# PRU_ICSSG0_PR1_CFG_SLV_local register map
Vendor: Texas Instruments
Peripheral module from a debugger description file (folder J7ES).
Registers are 32-bit, read-write, reset 0x0 unless marked. A register's access mark holds for its fields unless they carry their own. Offsets are as the file gives them; lines under a group give offsets from that group; [hi:lo] are bit positions; {n}, {i} and the like mark numbered series; 'fields as' and 'values as' point back to an identical list; <NAME> marks a mode.

## PRU_ICSSG0_PR1_CFG_SLV
0x00 ICSSG_PID_REG ro reset 0x6B00C900 — PID Register
  [31:0] ICSS_IDVER — Module ID field
0x04 ICSSG_HWDIS_REG ro reset not defined — HW DIS Register
  [7:0] HWDIS — HW Disable Observation
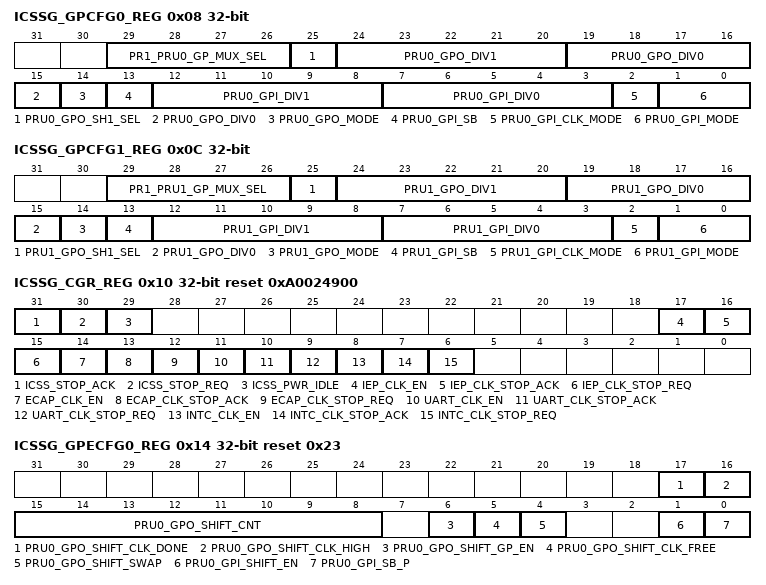
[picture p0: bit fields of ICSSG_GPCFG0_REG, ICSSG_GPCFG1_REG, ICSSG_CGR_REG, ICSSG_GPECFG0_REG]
0x08 ICSSG_GPCFG0_REG access not given — gpcfg0 Register
  [29:26] PR1_PRU0_GP_MUX_SEL rw
  [25] PRU0_GPO_SH1_SEL ro
  [24:20] PRU0_GPO_DIV1 rw
  [19:15] PRU0_GPO_DIV0 rw
  [14] PRU0_GPO_MODE rw
  [13] PRU0_GPI_SB — (access RW1C)
  [12:8] PRU0_GPI_DIV1 rw
  [7:3] PRU0_GPI_DIV0 rw
  [2] PRU0_GPI_CLK_MODE rw
  [1:0] PRU0_GPI_MODE rw
0x0C ICSSG_GPCFG1_REG access not given — gpcfg1 Register
  [29:26] PR1_PRU1_GP_MUX_SEL rw
  [25] PRU1_GPO_SH1_SEL ro
  [24:20] PRU1_GPO_DIV1 rw
  [19:15] PRU1_GPO_DIV0 rw
  [14] PRU1_GPO_MODE rw
  [13] PRU1_GPI_SB — (access RW1C)
  [12:8] PRU1_GPI_DIV1 rw
  [7:3] PRU1_GPI_DIV0 rw
  [2] PRU1_GPI_CLK_MODE rw
  [1:0] PRU1_GPI_MODE rw
0x10 ICSSG_CGR_REG access per field reset 0xA0024900 — cgr Register
  [31] ICSS_STOP_ACK rw, [30] ICSS_STOP_REQ ro, [29] ICSS_PWR_IDLE rw, [17] IEP_CLK_EN rw, [16] IEP_CLK_STOP_ACK ro, [15] IEP_CLK_STOP_REQ rw, [14] ECAP_CLK_EN rw, [13] ECAP_CLK_STOP_ACK ro, [12] ECAP_CLK_STOP_REQ rw, [11] UART_CLK_EN rw, [10] UART_CLK_STOP_ACK ro, [9] UART_CLK_STOP_REQ rw, [8] INTC_CLK_EN rw, [7] INTC_CLK_STOP_ACK ro, [6] INTC_CLK_STOP_REQ rw
0x14 ICSSG_GPECFG0_REG reset 0x23 — gpecfg0 Register
  [17] PRU0_GPO_SHIFT_CLK_DONE, [16] PRU0_GPO_SHIFT_CLK_HIGH, [15:8] PRU0_GPO_SHIFT_CNT, [6] PRU0_GPO_SHIFT_GP_EN, [5] PRU0_GPO_SHIFT_CLK_FREE, [4] PRU0_GPO_SHIFT_SWAP, [1] PRU0_GPI_SHIFT_EN, [0] PRU0_GPI_SB_P
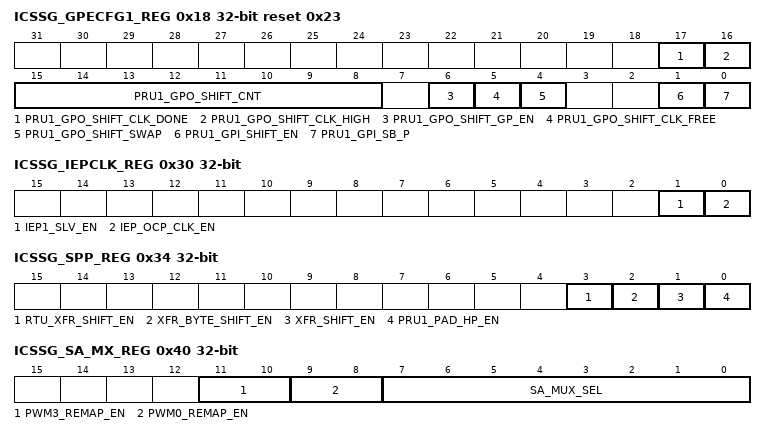
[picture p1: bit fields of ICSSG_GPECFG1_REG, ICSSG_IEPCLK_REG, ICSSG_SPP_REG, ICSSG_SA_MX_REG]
0x18 ICSSG_GPECFG1_REG reset 0x23 — gpecfg1 Register
  [17] PRU1_GPO_SHIFT_CLK_DONE, [16] PRU1_GPO_SHIFT_CLK_HIGH, [15:8] PRU1_GPO_SHIFT_CNT, [6] PRU1_GPO_SHIFT_GP_EN, [5] PRU1_GPO_SHIFT_CLK_FREE, [4] PRU1_GPO_SHIFT_SWAP, [1] PRU1_GPI_SHIFT_EN, [0] PRU1_GPI_SB_P
0x2C ICSSG_MII_RT_REG reset 0x1 — mii_rt Register
  [0] MII_RT_EVENT_EN
0x30 ICSSG_IEPCLK_REG — iepclk Register
  [1] IEP1_SLV_EN, [0] IEP_OCP_CLK_EN
0x34 ICSSG_SPP_REG — spp Register
  [3] RTU_XFR_SHIFT_EN, [2] XFR_BYTE_SHIFT_EN, [1] XFR_SHIFT_EN, [0] PRU1_PAD_HP_EN
0x3C ICSSG_CORE_SYNC_REG — Core Sync Register
  [0] CORE_VBUSP_SYNC_EN
0x40 ICSSG_SA_MX_REG — sa_mx Register
  [11:10] PWM3_REMAP_EN, [9:8] PWM0_REMAP_EN, [7:0] SA_MUX_SEL
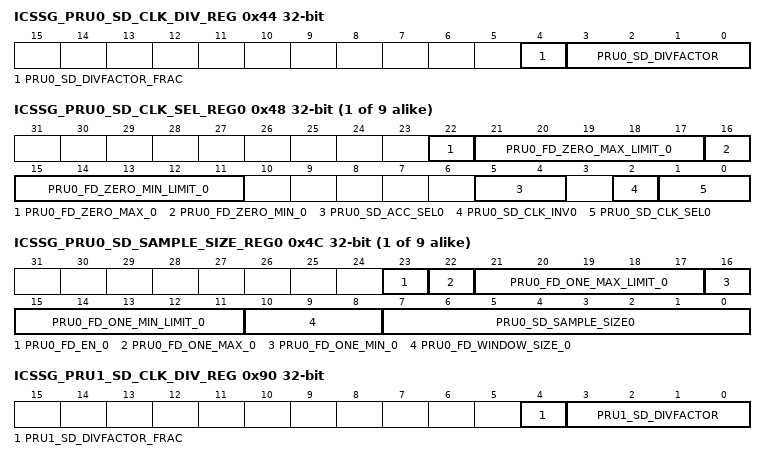
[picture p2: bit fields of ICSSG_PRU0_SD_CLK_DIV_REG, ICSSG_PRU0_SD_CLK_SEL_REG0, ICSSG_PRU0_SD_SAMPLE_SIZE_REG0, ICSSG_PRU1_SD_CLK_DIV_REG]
0x44 ICSSG_PRU0_SD_CLK_DIV_REG — SD Register
  [4] PRU0_SD_DIVFACTOR_FRAC, [3:0] PRU0_SD_DIVFACTOR
{0x48+8i} ICSSG_PRU0_SD_CLK_SEL_REG{i} (i=0..8) — SD Register
  [22] PRU0_FD_ZERO_MAX_{i}, [21:17] PRU0_FD_ZERO_MAX_LIMIT_{i}, [16] PRU0_FD_ZERO_MIN_{i}, [15:11] PRU0_FD_ZERO_MIN_LIMIT_{i}, [5:4] PRU0_SD_ACC_SEL{i}, [2] PRU0_SD_CLK_INV{i}, [1:0] PRU0_SD_CLK_SEL{i}
{0x4C+8i} ICSSG_PRU0_SD_SAMPLE_SIZE_REG{i} (i=0..8) — SD Register
  [23] PRU0_FD_EN_{i}, [22] PRU0_FD_ONE_MAX_{i}, [21:17] PRU0_FD_ONE_MAX_LIMIT_{i}, [16] PRU0_FD_ONE_MIN_{i}, [15:11] PRU0_FD_ONE_MIN_LIMIT_{i}, [10:8] PRU0_FD_WINDOW_SIZE_{i}, [7:0] PRU0_SD_SAMPLE_SIZE{i}
0x90 ICSSG_PRU1_SD_CLK_DIV_REG — SD Register
  [4] PRU1_SD_DIVFACTOR_FRAC, [3:0] PRU1_SD_DIVFACTOR
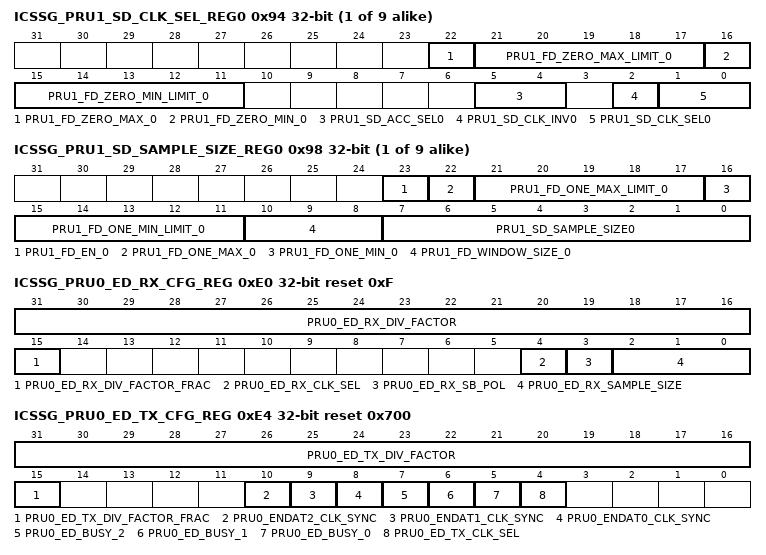
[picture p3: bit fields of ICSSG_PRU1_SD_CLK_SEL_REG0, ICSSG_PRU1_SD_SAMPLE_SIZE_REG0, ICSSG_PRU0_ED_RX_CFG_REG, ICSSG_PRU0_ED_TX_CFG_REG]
{0x94+8i} ICSSG_PRU1_SD_CLK_SEL_REG{i} (i=0..8) — SD Register
  [22] PRU1_FD_ZERO_MAX_{i}, [21:17] PRU1_FD_ZERO_MAX_LIMIT_{i}, [16] PRU1_FD_ZERO_MIN_{i}, [15:11] PRU1_FD_ZERO_MIN_LIMIT_{i}, [5:4] PRU1_SD_ACC_SEL{i}, [2] PRU1_SD_CLK_INV{i}, [1:0] PRU1_SD_CLK_SEL{i}
{0x98+8i} ICSSG_PRU1_SD_SAMPLE_SIZE_REG{i} (i=0..8) — SD Register
  [23] PRU1_FD_EN_{i}, [22] PRU1_FD_ONE_MAX_{i}, [21:17] PRU1_FD_ONE_MAX_LIMIT_{i}, [16] PRU1_FD_ONE_MIN_{i}, [15:11] PRU1_FD_ONE_MIN_LIMIT_{i}, [10:8] PRU1_FD_WINDOW_SIZE_{i}, [7:0] PRU1_SD_SAMPLE_SIZE{i}
0xE0 ICSSG_PRU0_ED_RX_CFG_REG reset 0xF — ED Register
  [31:16] PRU0_ED_RX_DIV_FACTOR, [15] PRU0_ED_RX_DIV_FACTOR_FRAC, [4] PRU0_ED_RX_CLK_SEL, [3] PRU0_ED_RX_SB_POL, [2:0] PRU0_ED_RX_SAMPLE_SIZE
0xE4 ICSSG_PRU0_ED_TX_CFG_REG access per field reset 0x700 — Register
  [31:16] PRU0_ED_TX_DIV_FACTOR rw, [15] PRU0_ED_TX_DIV_FACTOR_FRAC rw, [10] PRU0_ENDAT2_CLK_SYNC ro, [9] PRU0_ENDAT1_CLK_SYNC ro, [8] PRU0_ENDAT0_CLK_SYNC ro, [7] PRU0_ED_BUSY_2 ro, [6] PRU0_ED_BUSY_1 ro, [5] PRU0_ED_BUSY_0 ro, [4] PRU0_ED_TX_CLK_SEL rw
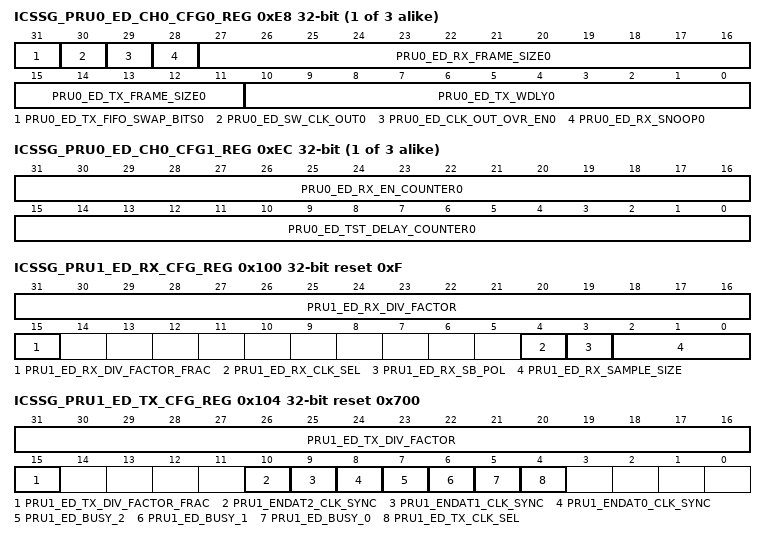
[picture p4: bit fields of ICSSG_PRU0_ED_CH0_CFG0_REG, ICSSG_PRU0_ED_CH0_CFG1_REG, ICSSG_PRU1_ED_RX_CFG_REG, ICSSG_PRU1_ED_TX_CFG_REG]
{0xE8+8i} ICSSG_PRU0_ED_CH{i}_CFG0_REG access per field (i=0..2) — ED Register
  [31] PRU0_ED_TX_FIFO_SWAP_BITS{i} rw, [30] PRU0_ED_SW_CLK_OUT{i} rw, [29] PRU0_ED_CLK_OUT_OVR_EN{i} rw, [28] PRU0_ED_RX_SNOOP{i} ro, [27:16] PRU0_ED_RX_FRAME_SIZE{i} rw, [15:11] PRU0_ED_TX_FRAME_SIZE{i} rw, [10:0] PRU0_ED_TX_WDLY{i} rw
{0xEC+8i} ICSSG_PRU0_ED_CH{i}_CFG1_REG (i=0..2) — ED Register
  [31:16] PRU0_ED_RX_EN_COUNTER{i}, [15:0] PRU0_ED_TST_DELAY_COUNTER{i}
0x100 ICSSG_PRU1_ED_RX_CFG_REG reset 0xF — ED Register
  [31:16] PRU1_ED_RX_DIV_FACTOR, [15] PRU1_ED_RX_DIV_FACTOR_FRAC, [4] PRU1_ED_RX_CLK_SEL, [3] PRU1_ED_RX_SB_POL, [2:0] PRU1_ED_RX_SAMPLE_SIZE
0x104 ICSSG_PRU1_ED_TX_CFG_REG access per field reset 0x700 — ED Register
  [31:16] PRU1_ED_TX_DIV_FACTOR rw, [15] PRU1_ED_TX_DIV_FACTOR_FRAC rw, [10] PRU1_ENDAT2_CLK_SYNC ro, [9] PRU1_ENDAT1_CLK_SYNC ro, [8] PRU1_ENDAT0_CLK_SYNC ro, [7] PRU1_ED_BUSY_2 ro, [6] PRU1_ED_BUSY_1 ro, [5] PRU1_ED_BUSY_0 ro, [4] PRU1_ED_TX_CLK_SEL rw
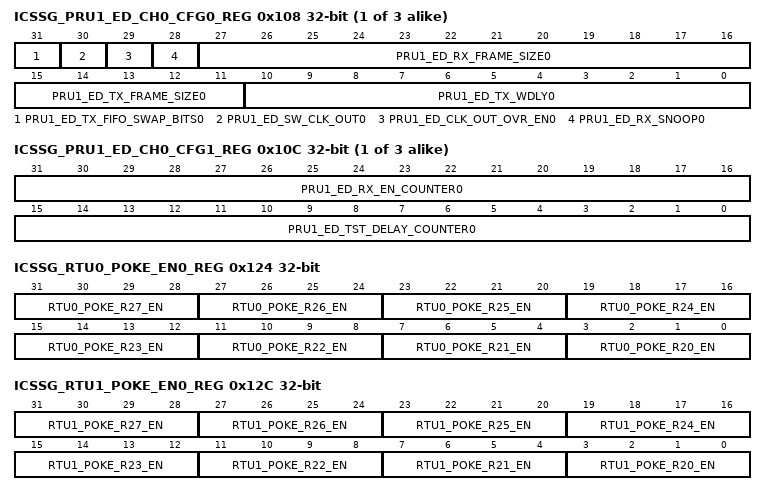
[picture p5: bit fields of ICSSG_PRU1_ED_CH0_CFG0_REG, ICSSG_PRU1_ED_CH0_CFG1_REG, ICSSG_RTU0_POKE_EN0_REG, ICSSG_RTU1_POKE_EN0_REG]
{0x108+8i} ICSSG_PRU1_ED_CH{i}_CFG0_REG access per field (i=0..2) — ED Register
  [31] PRU1_ED_TX_FIFO_SWAP_BITS{i} rw, [30] PRU1_ED_SW_CLK_OUT{i} rw, [29] PRU1_ED_CLK_OUT_OVR_EN{i} rw, [28] PRU1_ED_RX_SNOOP{i} ro, [27:16] PRU1_ED_RX_FRAME_SIZE{i} rw, [15:11] PRU1_ED_TX_FRAME_SIZE{i} rw, [10:0] PRU1_ED_TX_WDLY{i} rw
{0x10C+8i} ICSSG_PRU1_ED_CH{i}_CFG1_REG (i=0..2) — ED Register
  [31:16] PRU1_ED_RX_EN_COUNTER{i}, [15:0] PRU1_ED_TST_DELAY_COUNTER{i}
0x124 ICSSG_RTU0_POKE_EN0_REG — RTU PRU Poke Enable
  [4n-77:4n-80] RTU0_POKE_R{n}_EN (n=20..27)
0x12C ICSSG_RTU1_POKE_EN0_REG — RTU PRU Poke Enable
  [4n-77:4n-80] RTU1_POKE_R{n}_EN (n=20..27)
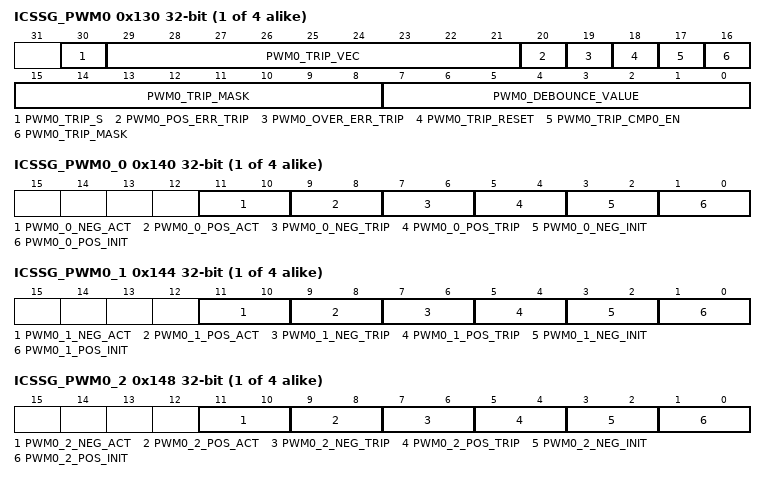
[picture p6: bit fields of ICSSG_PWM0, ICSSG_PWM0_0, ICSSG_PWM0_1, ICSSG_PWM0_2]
{0x130+4i} ICSSG_PWM{i} access per field (i=0..3) — Safety Config
  [30] PWM{i}_TRIP_S rw — Safety trip status
  [29:21] PWM{i}_TRIP_VEC ro — Safety trip trigger cause vector
  [20] PWM{i}_POS_ERR_TRIP rw — SW position saftey error trip
  [19] PWM{i}_OVER_ERR_TRIP rw — SW over safety error trip
  [18] PWM{i}_TRIP_RESET rw — SW reset safety flag
  [17] PWM{i}_TRIP_CMP0_EN rw — CMP0 reset safety trip clear enable
  [16:8] PWM{i}_TRIP_MASK rw — SW mask for safety trip, one hot
  [7:0] PWM{i}_DEBOUNCE_VALUE rw — debounce counter , defines the number of core_clk required for the pulse not to get rejected
{0x140+0xC*i} ICSSG_PWM{i}_0 (i=0..3) — State Config0
  [11:10] PWM{i}_0_NEG_ACT — Active neg state 00 toggle 01 L 10 H
  [9:8] PWM{i}_0_POS_ACT — Active pos state 00 toggle 01 L 10 H
  [7:6] PWM{i}_0_NEG_TRIP — Safety Trip neg state 00 z 01 L 10 H
  [5:4] PWM{i}_0_POS_TRIP — Safety Trip pos state 00 z 01 L 10 H
  [3:2] PWM{i}_0_NEG_INIT — Initial neg state 00 z 01 L 10 H
  [1:0] PWM{i}_0_POS_INIT — Initial pos state 00 z 01 L 10 H
{0x144+0xC*i} ICSSG_PWM{i}_1 (i=0..3) — State Config1
  [11:10] PWM{i}_1_NEG_ACT — Active neg state 00 toggle 01 L 10 H
  [9:8] PWM{i}_1_POS_ACT — Active pos state 00 toggle 01 L 10 H
  [7:6] PWM{i}_1_NEG_TRIP — Safety Trip neg state 00 z 01 L 10 H
  [5:4] PWM{i}_1_POS_TRIP — Safety Trip pos state 00 z 01 L 10 H
  [3:2] PWM{i}_1_NEG_INIT — Initial neg state 00 z 01 L 10 H
  [1:0] PWM{i}_1_POS_INIT — Initial pos state 00 z 01 L 10 H
{0x148+0xC*i} ICSSG_PWM{i}_2 (i=0..3) — State Config2
  [11:10] PWM{i}_2_NEG_ACT — Active neg state 00 toggle 01 L 10 H
  [9:8] PWM{i}_2_POS_ACT — Active pos state 00 toggle 01 L 10 H
  [7:6] PWM{i}_2_NEG_TRIP — Safety Trip neg state 00 z 01 L 10 H
  [5:4] PWM{i}_2_POS_TRIP — Safety Trip pos state 00 z 01 L 10 H
  [3:2] PWM{i}_2_NEG_INIT — Initial neg state 00 z 01 L 10 H
  [1:0] PWM{i}_2_POS_INIT — Initial pos state 00 z 01 L 10 H
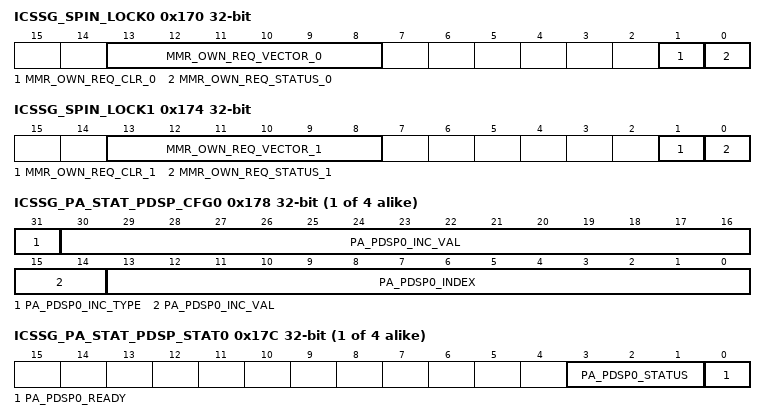
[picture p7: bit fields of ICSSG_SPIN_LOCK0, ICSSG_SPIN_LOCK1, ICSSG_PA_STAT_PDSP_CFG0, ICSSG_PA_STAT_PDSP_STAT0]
0x170 ICSSG_SPIN_LOCK0 access per field (reset mask 0x3F02) — Spin Lock
  [13:8] MMR_OWN_REQ_VECTOR_0 rw — Spin Lock flag Vector
  [1] MMR_OWN_REQ_CLR_0 wo — Spin Lock Status Clear
  [0] MMR_OWN_REQ_STATUS_0 ro — Spin Lock Status
0x174 ICSSG_SPIN_LOCK1 access per field (reset mask 0x3F02) — Spin Lock
  [13:8] MMR_OWN_REQ_VECTOR_1 rw — Spin Lock flag Vector
  [1] MMR_OWN_REQ_CLR_1 wo — Spin Lock Status Clear
  [0] MMR_OWN_REQ_STATUS_1 ro — Spin Lock Status
{0x178+8i} ICSSG_PA_STAT_PDSP_CFG{i} (i=0..3) — PA STATS PDSP{i} Vector
  [31] PA_PDSP{i}_INC_TYPE, [30:14] PA_PDSP{i}_INC_VAL, [13:0] PA_PDSP{i}_INDEX
{0x17C+8i} ICSSG_PA_STAT_PDSP_STAT{i} ro (i=0..3) — PA STATS PDSP{i} Status
  [3:1] PA_PDSP{i}_STATUS, [0] PA_PDSP{i}_READY
